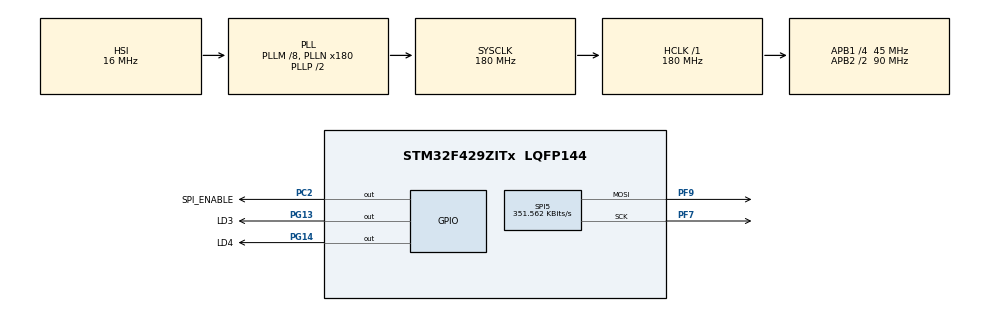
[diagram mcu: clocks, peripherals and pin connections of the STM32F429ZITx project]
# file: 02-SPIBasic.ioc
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Mcu.Family=STM32F4
Mcu.Name=STM32F429ZITx
Mcu.Package=LQFP144
NVIC.PriorityGroup=NVIC_PRIORITYGROUP_0
PA13.Mode=Serial_Wire
PA13.Signal=SYS_JTMS-SWDIO
PA14.Mode=Serial_Wire
PA14.Signal=SYS_JTCK-SWCLK
PC2.GPIO_Label=SPI_ENABLE
PC2.PinState=GPIO_PIN_SET
PC2.Signal=GPIO_Output
PF7.Mode=TX_Only_Simplex_Unidirect_Master
PF7.Signal=SPI5_SCK
PF9.Mode=TX_Only_Simplex_Unidirect_Master
PF9.Signal=SPI5_MOSI
PG13.GPIO_Label=LD3
PG13.PinState=GPIO_PIN_SET
PG13.Signal=GPIO_Output
PG14.GPIO_Label=LD4
PG14.PinState=GPIO_PIN_SET
PG14.Signal=GPIO_Output
ProjectManager.HeapSize=0x200
ProjectManager.StackSize=0x400
ProjectManager.TargetToolchain=EWARM V8
RCC.48MHZClocksFreq_Value=51428571.428571425
RCC.AHBFreq_Value=180000000
RCC.APB1CLKDivider=RCC_HCLK_DIV4
RCC.APB1Freq_Value=45000000
RCC.APB1TimFreq_Value=90000000
RCC.APB2CLKDivider=RCC_HCLK_DIV2
RCC.APB2Freq_Value=90000000
RCC.APB2TimFreq_Value=180000000
RCC.CortexFreq_Value=180000000
RCC.HCLKFreq_Value=180000000
RCC.HSE_VALUE=8000000
RCC.HSI_VALUE=16000000
RCC.LSE_VALUE=32768
RCC.PLLM=8
RCC.PLLN=180
RCC.PLLQ=7
RCC.SYSCLKFreq_VALUE=180000000
RCC.SYSCLKSource=RCC_SYSCLKSOURCE_PLLCLK
RCC.VCOOutputFreq_Value=360000000
SPI5.BaudRatePrescaler=SPI_BAUDRATEPRESCALER_256
SPI5.CLKPhase=SPI_PHASE_1EDGE
SPI5.CLKPolarity=SPI_POLARITY_LOW
SPI5.CalculateBaudRate=351.562 KBits/s
SPI5.Direction=SPI_DIRECTION_2LINES
SPI5.Mode=SPI_MODE_MASTER
SPI5.VirtualType=VM_MASTER
board=STM32F429I-DISC1

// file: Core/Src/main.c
/* USER CODE BEGIN Header */
/**
  ******************************************************************************
  * @file           : main.c
  * @brief          : Main program body
  ******************************************************************************
  * @attention
  *
  * Copyright (c) 2022 STMicroelectronics.
  * All rights reserved.
  *
  * This software is licensed under terms that can be found in the LICENSE file
  * in the root directory of this software component.
  * If no LICENSE file comes with this software, it is provided AS-IS.
  *
  ******************************************************************************
  */
/* USER CODE END Header */
#include "main.h"

SPI_HandleTypeDef hspi5;

void SystemClock_Config(void);
static void MX_GPIO_Init(void);
static void MX_SPI5_Init(void);

int main(void)
{
  /* USER CODE BEGIN 1 */
  uint8_t data[10] = { 0x01, 0x02, 0x04, 0x08, 0x10, 0x20, 0x40, 0x80, 0x55, 0x00 };
  /* USER CODE END 1 */

  /* MCU Configuration--------------------------------------------------------*/

  /* Reset of all peripherals, Initializes the Flash interface and the Systick. */
  HAL_Init();

  /* Configure the system clock */
  SystemClock_Config();

  /* Initialize all configured peripherals */
  MX_GPIO_Init();
  MX_SPI5_Init();
  /* USER CODE BEGIN 2 */
  HAL_GPIO_WritePin( SPI_ENABLE_GPIO_Port, SPI_ENABLE_Pin, GPIO_PIN_SET );
  HAL_Delay(100);
  HAL_GPIO_WritePin( SPI_ENABLE_GPIO_Port, SPI_ENABLE_Pin, GPIO_PIN_RESET );
  HAL_SPI_Transmit( &hspi5, data, 10u, 300u );
  HAL_GPIO_WritePin( SPI_ENABLE_GPIO_Port, SPI_ENABLE_Pin, GPIO_PIN_SET );
  /* USER CODE END 2 */

  /* Infinite loop */
  while (1)
  {

    /* USER CODE BEGIN 3 */
    HAL_GPIO_WritePin( LD3_GPIO_Port, LD3_Pin, GPIO_PIN_RESET );
    HAL_GPIO_WritePin( LD4_GPIO_Port, LD4_Pin, GPIO_PIN_RESET );
    HAL_Delay( 1000 );
    HAL_GPIO_WritePin( LD3_GPIO_Port, LD3_Pin, GPIO_PIN_SET );
    HAL_GPIO_WritePin( LD4_GPIO_Port, LD4_Pin, GPIO_PIN_SET );
    HAL_Delay( 1000 );
  }
  /* USER CODE END 3 */
}

void SystemClock_Config(void)
{
  RCC_OscInitTypeDef RCC_OscInitStruct = {0};
  RCC_ClkInitTypeDef RCC_ClkInitStruct = {0};

  /** Configure the main internal regulator output voltage
  */
  __HAL_RCC_PWR_CLK_ENABLE();
  __HAL_PWR_VOLTAGESCALING_CONFIG(PWR_REGULATOR_VOLTAGE_SCALE1);

  /** Initializes the RCC Oscillators according to the specified parameters
  * in the RCC_OscInitTypeDef structure.
  */
  RCC_OscInitStruct.OscillatorType = RCC_OSCILLATORTYPE_HSI;
  RCC_OscInitStruct.HSIState = RCC_HSI_ON;
  RCC_OscInitStruct.HSICalibrationValue = RCC_HSICALIBRATION_DEFAULT;
  RCC_OscInitStruct.PLL.PLLState = RCC_PLL_ON;
  RCC_OscInitStruct.PLL.PLLSource = RCC_PLLSOURCE_HSI;
  RCC_OscInitStruct.PLL.PLLM = 8;
  RCC_OscInitStruct.PLL.PLLN = 180;
  RCC_OscInitStruct.PLL.PLLP = RCC_PLLP_DIV2;
  RCC_OscInitStruct.PLL.PLLQ = 7;
  if (HAL_RCC_OscConfig(&RCC_OscInitStruct) != HAL_OK)
  {
    Error_Handler();
  }

  /** Activate the Over-Drive mode
  */
  if (HAL_PWREx_EnableOverDrive() != HAL_OK)
  {
    Error_Handler();
  }

  /** Initializes the CPU, AHB and APB buses clocks
  */
  RCC_ClkInitStruct.ClockType = RCC_CLOCKTYPE_HCLK|RCC_CLOCKTYPE_SYSCLK
                              |RCC_CLOCKTYPE_PCLK1|RCC_CLOCKTYPE_PCLK2;
  RCC_ClkInitStruct.SYSCLKSource = RCC_SYSCLKSOURCE_PLLCLK;
  RCC_ClkInitStruct.AHBCLKDivider = RCC_SYSCLK_DIV1;
  RCC_ClkInitStruct.APB1CLKDivider = RCC_HCLK_DIV4;
  RCC_ClkInitStruct.APB2CLKDivider = RCC_HCLK_DIV2;

  if (HAL_RCC_ClockConfig(&RCC_ClkInitStruct, FLASH_LATENCY_5) != HAL_OK)
  {
    Error_Handler();
  }
}

static void MX_SPI5_Init(void)
{

  /* SPI5 parameter configuration*/
  hspi5.Instance = SPI5;
  hspi5.Init.Mode = SPI_MODE_MASTER;
  hspi5.Init.Direction = SPI_DIRECTION_2LINES;
  hspi5.Init.DataSize = SPI_DATASIZE_8BIT;
  hspi5.Init.CLKPolarity = SPI_POLARITY_LOW;
  hspi5.Init.CLKPhase = SPI_PHASE_1EDGE;
  hspi5.Init.NSS = SPI_NSS_SOFT;
  hspi5.Init.BaudRatePrescaler = SPI_BAUDRATEPRESCALER_256;
  hspi5.Init.FirstBit = SPI_FIRSTBIT_MSB;
  hspi5.Init.TIMode = SPI_TIMODE_DISABLE;
  hspi5.Init.CRCCalculation = SPI_CRCCALCULATION_DISABLE;
  hspi5.Init.CRCPolynomial = 10;
  if (HAL_SPI_Init(&hspi5) != HAL_OK)
  {
    Error_Handler();
  }

}

static void MX_GPIO_Init(void)
{
  GPIO_InitTypeDef GPIO_InitStruct = {0};

  /* GPIO Ports Clock Enable */
  __HAL_RCC_GPIOF_CLK_ENABLE();
  __HAL_RCC_GPIOC_CLK_ENABLE();
  __HAL_RCC_GPIOA_CLK_ENABLE();
  __HAL_RCC_GPIOG_CLK_ENABLE();

  /*Configure GPIO pin Output Level */
  HAL_GPIO_WritePin(SPI_ENABLE_GPIO_Port, SPI_ENABLE_Pin, GPIO_PIN_SET);

  /*Configure GPIO pin Output Level */
  HAL_GPIO_WritePin(GPIOG, LD3_Pin|LD4_Pin, GPIO_PIN_SET);

  /*Configure GPIO pin : SPI_ENABLE_Pin */
  GPIO_InitStruct.Pin = SPI_ENABLE_Pin;
  GPIO_InitStruct.Mode = GPIO_MODE_OUTPUT_PP;
  GPIO_InitStruct.Pull = GPIO_NOPULL;
  GPIO_InitStruct.Speed = GPIO_SPEED_FREQ_LOW;
  HAL_GPIO_Init(SPI_ENABLE_GPIO_Port, &GPIO_InitStruct);

  /*Configure GPIO pins : LD3_Pin LD4_Pin */
  GPIO_InitStruct.Pin = LD3_Pin|LD4_Pin;
  GPIO_InitStruct.Mode = GPIO_MODE_OUTPUT_PP;
  GPIO_InitStruct.Pull = GPIO_NOPULL;
  GPIO_InitStruct.Speed = GPIO_SPEED_FREQ_LOW;
  HAL_GPIO_Init(GPIOG, &GPIO_InitStruct);

}

void Error_Handler(void)
{
  __disable_irq();
  while (1)
  {
  }
}
